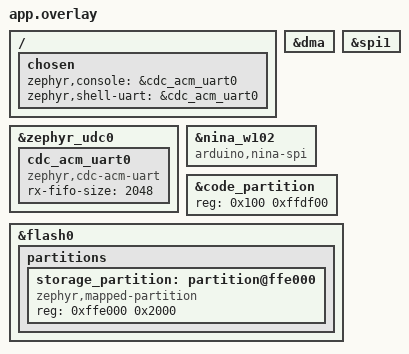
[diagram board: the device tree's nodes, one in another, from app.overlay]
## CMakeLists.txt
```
cmake_minimum_required(VERSION 3.28.0)
find_package(Zephyr REQUIRED HINTS $ENV{ZEPHYR_BASE})
project(usb_console)

target_sources(app PRIVATE src/main.c src/log_ram.c src/kv_store.c src/imu_cal.c src/imu_cal_codec.c src/wifi_profile.c
  src/time_sync.c src/time_offset.c
  src/imu_stream.c src/imu_raw_batch.c src/imu_raw_packet.c src/imu_raw_time.c
  src/imu_tick_clock.c src/imu_raw_queue.c src/imu_raw_mqtt.c src/imu_raw_status.c
  drivers/nina/nina_wifi.c drivers/nina/nina_net.c drivers/nina/nina_socket.c
  drivers/nina/nina_dns.c)
target_include_directories(app PRIVATE src drivers/lsm6dso)
# Keep Zephyr's Kconfig and devicetree bindings while using local driver copies.
function(use_local_driver_sources target pattern replacement_dir)
  get_target_property(sources ${target} SOURCES)
  set(updated_sources)
  set(replaced 0)
  foreach(source IN LISTS sources)
    if(source MATCHES "${pattern}")
      get_filename_component(filename "${source}" NAME)
      list(APPEND updated_sources "${CMAKE_CURRENT_SOURCE_DIR}/${replacement_dir}/${filename}")
      math(EXPR replaced "${replaced} + 1")
    else()
      list(APPEND updated_sources "${source}")
    endif()
  endforeach()
  if(replaced EQUAL 0)
    message(FATAL_ERROR "No sources replaced in ${target}; check the Zephyr version and configuration")
  endif()
  set_property(TARGET ${target} PROPERTY SOURCES "${updated_sources}")
endfunction()

use_local_driver_sources(drivers__i2c "(^|/)i2c_dw\\.c$" drivers/i2c_dw)
if(CONFIG_I2C_DW_RP2040_DMA)
  target_sources(drivers__i2c PRIVATE drivers/i2c_dw/i2c_dw_rp2040_commands.c)
endif()
target_include_directories(drivers__i2c PRIVATE "${ZEPHYR_BASE}/drivers/i2c")

use_local_driver_sources(drivers__sensor__st__lsm6dso "(^|/)lsm6dso(_shub|_trigger)?\\.c$" drivers/lsm6dso)
use_local_driver_sources(drivers__sensor "(^|/)sensor_shell\\.c$" drivers/sensor_shell)
target_include_directories(drivers__sensor PRIVATE ${ZEPHYR_BASE}/drivers/sensor)
target_sources(drivers__sensor__st__lsm6dso PRIVATE drivers/lsm6dso/lsm6dso_fifo.c)
target_sources(drivers__sensor__st__lsm6dso PRIVATE drivers/lsm6dso/lsm6dso_cal.c)
target_sources(drivers__sensor__st__lsm6dso PRIVATE drivers/lsm6dso/lsm6dso_fifo_hw.c)
target_sources(drivers__sensor__st__lsm6dso PRIVATE drivers/lsm6dso/lsm6dso_fifo_irq.c)
if(CONFIG_SENSOR_ASYNC_API)
  target_sources(drivers__sensor__st__lsm6dso PRIVATE
    drivers/lsm6dso/lsm6dso_fifo_decoder.c
    drivers/lsm6dso/lsm6dso_compat.c
    drivers/lsm6dso/lsm6dso_stream.c)
endif()
```

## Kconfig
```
mainmenu "USB console"
source "Kconfig.zephyr"

config I2C_DW_RP2040_DMA
	bool "RP2040 I2C0 DMA reads"
	depends on SOC_RP2040 && I2C_DW && DMA_RPI_PICO && SHELL && !SMP
	depends on !I2C_DW_LPSS_DMA

config WIFI_NINA_LOCAL
	bool "NINA SPI Wi-Fi offload"
	default y
	select NET_L2_WIFI_MGMT
	select WIFI_OFFLOAD
	select NET_SOCKETS
	select NET_SOCKETS_OFFLOAD

config NINA_SPI_FREQUENCY
	int "NINA SPI frequency in Hz"
	default 8000000
	range 1000000 10000000
	depends on WIFI_NINA_LOCAL

config NINA_TCP_MAX_IO
	int "Maximum bytes per NINA TCP send"
	default 3584
	range 1 3584
	depends on WIFI_NINA_LOCAL
	help
	  Bounds each TCP send to leave room for framing in the NINA SPI
	  command buffer. A RAW batch of up to 2448 bytes plus its MQTT
	  header is sent in one command with the default.

config NINA_SEND_RETRY_MS
	int "Delay before retrying a full NINA TCP send buffer"
	default 1
	range 1 1000
	depends on WIFI_NINA_LOCAL

config NINA_NTP_SERVER
	string "NTP server hostname or IPv4 address"
	default ""
	depends on WIFI_NINA_LOCAL
	help
	  Empty uses the default gateway, normally the PC that provides the
	  Wi-Fi network and runs an NTP server for the board.

config NINA_NTP_PORT
	int "NTP server UDP port"
	default 123
	range 1 65535
	depends on WIFI_NINA_LOCAL

config NINA_NTP_INTERVAL_MS
	int "Interval between NTP queries in milliseconds"
	default 2000
	range 250 3600000
	depends on WIFI_NINA_LOCAL
	help
	  Queries go to a server on the local network. Do not point short
	  intervals at public servers.

# Removed with the last cleanup step; lets a new image be written without
# pressing the BOOTSEL button while the cleanup is being verified.
config NINA_BENCHMARK_BOOTSEL
	bool "Enable BOOTSEL command"
	depends on SOC_RP2040 && SHELL
```

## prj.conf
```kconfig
CONFIG_SERIAL=y
CONFIG_CONSOLE=y
CONFIG_UART_CONSOLE=y
CONFIG_UART_LINE_CTRL=y
CONFIG_SHELL=y
# Keep Wi-Fi credentials out of shell command history.
CONFIG_SHELL_HISTORY=n
CONFIG_SHELL_BACKEND_SERIAL_RX_RING_BUFFER_SIZE=2048
CONFIG_SHELL_CMD_BUFF_SIZE=512
CONFIG_SHELL_STACK_SIZE=3072
CONFIG_MAIN_STACK_SIZE=2048
CONFIG_GPIO=y
CONFIG_GPIO_SHELL=y
CONFIG_I2C=y
CONFIG_SPI=y
CONFIG_I2C_SHELL=y
CONFIG_I2C_SHELL_BUFFER_SIZE=64
CONFIG_SENSOR=y
CONFIG_SENSOR_SHELL=y
CONFIG_SENSOR_SHELL_STREAM=y
CONFIG_SENSOR_SHELL_THREAD_STACK_SIZE=3072
CONFIG_STACK_SENTINEL=y
CONFIG_POLL=y
CONFIG_LSM6DSO=y
CONFIG_REBOOT=y
CONFIG_THREAD_ANALYZER=y
CONFIG_THREAD_ANALYZER_USE_PRINTK=y
CONFIG_LOG=y
CONFIG_LOG_OUTPUT=y
CONFIG_LOG_TIMESTAMP_64BIT=y
CONFIG_LOG_CMDS=y
CONFIG_LOG_RUNTIME_FILTERING=y
CONFIG_SHELL_LOG_BACKEND=n
CONFIG_LOG_BACKEND_UART=n

CONFIG_USB_DEVICE_STACK_NEXT=y
CONFIG_USBD_CDC_ACM_LOG_LEVEL_OFF=y
CONFIG_CDC_ACM_SERIAL_INITIALIZE_AT_BOOT=y
CONFIG_CDC_ACM_SERIAL_PID=0x0004
CONFIG_CDC_ACM_SERIAL_PRODUCT_STRING="Zephyr USB Console"

# Measure active time from CPU idle windows, including interrupts.
CONFIG_CPU_LOAD=y
CONFIG_CPU_LOAD_BACKEND_IDLE_HOOK=y

# Use DMA for eligible I2C0 reads.
CONFIG_DMA=y
CONFIG_I2C_DW_RP2040_DMA=y

# NINA Wi-Fi management and socket offload.
CONFIG_NETWORKING=y
CONFIG_WIFI=y
CONFIG_WIFI_CREDENTIALS=y
CONFIG_WIFI_CREDENTIALS_BACKEND_SETTINGS=y
CONFIG_WIFI_NINA_LOCAL=y
CONFIG_NET_IPV4=y
CONFIG_NET_TCP=y
CONFIG_SHELL_BACKEND_TELNET=y
CONFIG_ZVFS_POLL_MAX=16
CONFIG_NET_ZPERF=y
CONFIG_NET_ZPERF_IPERF3=y
CONFIG_NET_ZPERF_SERVER=y
CONFIG_NET_L2_WIFI_SHELL=y
CONFIG_NET_SHELL=y
CONFIG_MQTT_LIB=y
# Network event callbacks may print Wi-Fi results through the shell. Measured
# peak use is 924 bytes including a Wi-Fi scan.
CONFIG_NET_MGMT_EVENT_STACK_SIZE=2048
# Every socket is offloaded to the NINA, so Zephyr's own IP stack carries no
# traffic ("net conn" stays empty). Keep its packet buffers and connection
# tables at a minimum instead of the defaults sized for native networking.
CONFIG_NET_PKT_RX_COUNT=2
CONFIG_NET_PKT_TX_COUNT=2
CONFIG_NET_BUF_RX_COUNT=4
CONFIG_NET_BUF_TX_COUNT=4
CONFIG_NET_MAX_CONTEXTS=2
CONFIG_NET_MAX_CONN=2
# Zephyr derives the size of the file descriptor table from NET_MAX_CONTEXTS,
# which no longer reflects the sockets in use. Size it for the ten NINA
# sockets, stdin/stdout/stderr and the socket service's eventfd. With too few,
# accepting a Telnet client fails in a tight loop.
CONFIG_ZVFS_OPEN_MAX=16
CONFIG_WIFI_ESP_AT=n
# Temporary non-cryptographic random generator for network testing; no TLS.
CONFIG_TEST_RANDOM_GENERATOR=y
CONFIG_NET_IPV6=n

# Persist the most recently successful Wi-Fi connection.
CONFIG_FLASH=y
CONFIG_FLASH_MAP=y
CONFIG_NVS=y
CONFIG_SETTINGS=y
CONFIG_SETTINGS_NVS=y

# Identifies the board in automatically assigned IMU session IDs.
CONFIG_HWINFO=y
```

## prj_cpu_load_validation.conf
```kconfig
# Test-only synthetic thread and timer-ISR workload.
CONFIG_IMU_CPU_LOAD_VALIDATION=y
```

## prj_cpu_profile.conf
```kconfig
# Thread-only profiling; scheduler accounting includes interrupt time.
CONFIG_IMU_CPU_PROFILE=y
```

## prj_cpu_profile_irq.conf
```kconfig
# Optional IRQ sampling; can perturb high-rate I2C and cause FIFO overrun.
CONFIG_IMU_CPU_PROFILE=y
CONFIG_TRACING=y
CONFIG_TRACING_NONE=y
CONFIG_TRACING_ISR=y
CONFIG_IMU_CPU_PROFILE_IRQS=y
```

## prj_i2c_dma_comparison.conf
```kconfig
# Hardware validation commands for I2C DMA.
CONFIG_DMA=y
CONFIG_I2C_DW_RP2040_DMA=y
CONFIG_IMU_I2C_VALIDATION=y
CONFIG_IMU_CPU_LOAD_VALIDATION=y
CONFIG_I2C_SHELL_BUFFER_SIZE=64
```

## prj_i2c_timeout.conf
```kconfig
CONFIG_IMU_I2C_VALIDATION=y
CONFIG_I2C_TRANSFER_TIMEOUT_MS=2
```

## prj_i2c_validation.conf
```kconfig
CONFIG_IMU_I2C_VALIDATION=y
```

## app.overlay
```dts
/ {
	chosen {
		zephyr,console = &cdc_acm_uart0;
		zephyr,shell-uart = &cdc_acm_uart0;
	};
};

&zephyr_udc0 {
	cdc_acm_uart0: cdc_acm_uart0 {
		compatible = "zephyr,cdc-acm-uart";
		rx-fifo-size = <2048>;
	};
};

&dma {
	status = "okay";
};

&spi1 {
	status = "okay";
};

&nina_w102 {
	compatible = "arduino,nina-spi";
};

/* Reserve the last two erase sectors for settings; keep the image separate. */
&code_partition {
	reg = <0x100 0xffdf00>;
};

&flash0 {
	partitions {
		storage_partition: partition@ffe000 {
			compatible = "zephyr,mapped-partition";
			reg = <0xffe000 0x2000>;
		};
	};
};
```

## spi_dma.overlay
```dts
#include <zephyr/dt-bindings/dma/rpi-pico-dma-rp2040.h>

&spi1 {
	dmas = <&dma 0 RPI_PICO_DMA_SLOT_SPI1_TX 0>,
	       <&dma 1 RPI_PICO_DMA_SLOT_SPI1_RX 0>;
	dma-names = "tx", "rx";
};
```

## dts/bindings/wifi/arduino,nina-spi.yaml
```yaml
description: Arduino NINA WiFi firmware SPI interface
compatible: "arduino,nina-spi"
include: spi-device.yaml
properties:
  ready-gpios:
    type: phandle-array
    required: true
  reset-gpios:
    type: phandle-array
    required: true
  irq-gpios:
    type: phandle-array
    required: true
```

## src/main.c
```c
#include <zephyr/kernel.h>
#include <zephyr/debug/thread_analyzer.h>
#include <zephyr/logging/log.h>
#include <zephyr/shell/shell.h>
#include "wifi_profile.h"
#include "../drivers/nina/nina_proto.h"
#include "time_sync.h"
#include "imu_cal.h"
#include "kv_store.h"

LOG_MODULE_REGISTER(usb_console, LOG_LEVEL_INF);

static int cmd_nina_version(const struct shell *sh, size_t argc, char **argv)
{
	uint8_t version[16];
	size_t len;
	int ret;

	ARG_UNUSED(argc);
	ARG_UNUSED(argv);
	ret = nina_request(0x37, NULL, 0, false, false, version, sizeof(version) - 1, &len);
	if (ret) {
		shell_error(sh, "NINA version request failed: %d", ret);
		return ret;
	}
	version[len] = '\0';
	shell_print(sh, "NINA firmware: %s", version);
	return 0;
}

SHELL_STATIC_SUBCMD_SET_CREATE(nina_commands,
	SHELL_CMD(version, NULL, "Show NINA firmware version", cmd_nina_version),
	SHELL_SUBCMD_SET_END);
SHELL_CMD_REGISTER(nina, &nina_commands, "NINA Wi-Fi module", NULL);

/* Thread Analyzer's callback has no user context, so serialize access to it. */
K_MUTEX_DEFINE(ps_lock);
static const struct shell *ps_shell;

static void ps_print_thread(struct thread_analyzer_info *info)
{
	shell_print(ps_shell, "%-20s CPU: %3u%%  STACK: %zu / %zu bytes",
		    info->name, info->utilization, info->stack_used,
		    info->stack_size);
}

static int cmd_ps(const struct shell *sh, size_t argc, char **argv)
{
	ARG_UNUSED(argc);
	ARG_UNUSED(argv);
	k_mutex_lock(&ps_lock, K_FOREVER);
	ps_shell = sh;
	thread_analyzer_run(ps_print_thread, 0);
	ps_shell = NULL;
	k_mutex_unlock(&ps_lock);
	return 0;
}

SHELL_SUBCMD_ADD((kernel), ps, NULL, "Show thread CPU and stack usage", cmd_ps,
		 1, 0);

int main(void)
{
	int ret;

	LOG_INF("USB console started");
	ret = kv_store_init();
	if (ret) {
		LOG_ERR("Could not initialize settings: %d", ret);
	}
	ret = imu_cal_init();
	if (ret) {
		LOG_ERR("Could not set up the IMU calibration: %d", ret);
	}
	time_sync_init();
	(void)wifi_profile_init();
	return 0;
}
```

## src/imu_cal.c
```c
/* SPDX-License-Identifier: Apache-2.0 */

#include <errno.h>
#include <stdlib.h>
#include <string.h>
#include <zephyr/device.h>
#include <zephyr/devicetree.h>
#include <zephyr/shell/shell.h>
#include <zephyr/sys/printk.h>
#include "imu_cal.h"
#include "kv_store.h"

static const struct device *const imu = DEVICE_DT_GET(DT_NODELABEL(lsm6dsox));

static bool lookup(enum lsm6dso_cal_kind kind, uint32_t gain, struct lsm6dso_cal *cal)
{
	char key[IMU_CAL_KEY_MAX];
	uint8_t blob[IMU_CAL_BLOB_SIZE];
	ssize_t len;

	if (imu_cal_key(kind, gain, key, sizeof(key)) < 0) {
		return false;
	}
	len = kv_store_get(key, blob, sizeof(blob));
	return len > 0 && imu_cal_decode(blob, len, kind, gain, cal) == 0;
}

int imu_cal_init(void)
{
	if (!device_is_ready(imu)) {
		return -ENODEV;
	}
	lsm6dso_cal_set_lookup(imu, lookup);
	return 0;
}

static void print_one(const struct shell *sh, const char *name, const char *unit,
		      enum lsm6dso_cal_kind kind, uint32_t gain, bool calibrated)
{
	char key[IMU_CAL_KEY_MAX];

	(void)imu_cal_key(kind, gain, key, sizeof(key));
	shell_print(sh, "  %-6s %s (%u %s/LSB, key %s)", name,
		    calibrated ? "calibrated" : "nominal", (unsigned int)gain, unit, key);
}

/* Prints one bias value, kept as LSB << 8, with two decimals. */
static void format_bias(char *text, size_t size, int32_t value)
{
	int32_t hundredths = (int32_t)(((int64_t)value * 100 +
					(value >= 0 ? 128 : -128)) / 256);

	snprintk(text, size, "%s%d.%02d", hundredths < 0 ? "-" : "",
		 (int)(abs(hundredths) / 100), (int)(abs(hundredths) % 100));
}

static void print_bias(const struct shell *sh, const struct lsm6dso_cal_status *status)
{
	char x[12], y[12], z[12];

	format_bias(x, sizeof(x), status->gyro_bias[0]);
	format_bias(y, sizeof(y), status->gyro_bias[1]);
	format_bias(z, sizeof(z), status->gyro_bias[2]);
	if (status->gyro_bias_updates > 0) {
		shell_print(sh, "  gyro bias: %s %s %s LSB (tracked at rest, %u updates, %u rejected)",
			    x, y, z, (unsigned int)status->gyro_bias_updates,
			    (unsigned int)status->gyro_bias_rejected);
	} else {
		shell_print(sh, "  gyro bias: %s %s %s LSB (%s, %u rejected)", x, y, z,
			    status->gyro_calibrated ? "stored" : "none",
			    (unsigned int)status->gyro_bias_rejected);
	}
}

int imu_cal_shell(const struct shell *sh, size_t argc, char **argv)
{
	struct lsm6dso_cal_status status;

	if (!device_is_ready(imu)) {
		shell_error(sh, "IMU not ready");
		return -ENODEV;
	}
	if (argc > 1 && strcmp(argv[1], "reload") == 0) {
		lsm6dso_cal_reload(imu);
	} else if (argc > 1 && strcmp(argv[1], "zero") == 0) {
		int ret = lsm6dso_cal_zero(imu);

		if (ret == -EBUSY) {
			shell_error(sh, "The sensor is streaming; the bias is tracked from the stream");
		} else if (ret == -EAGAIN) {
			shell_error(sh, "The sensor did not stay at rest");
		} else if (ret == -ERANGE) {
			shell_error(sh, "The reading is too far from the stored bias");
		} else if (ret) {
			shell_error(sh, "Could not read the sensor: %d", ret);
		}
		if (ret) {
			return ret;
		}
	} else if (argc > 1) {
		shell_error(sh, "usage: imu cal [reload|zero]");
		return -EINVAL;
	}
	lsm6dso_cal_status(imu, &status);
	shell_print(sh, "conversion:");
	print_one(sh, "accel:", "ug", LSM6DSO_CAL_ACCEL, status.accel_gain, status.accel_calibrated);
	print_one(sh, "gyro:", "udps", LSM6DSO_CAL_GYRO, status.gyro_gain, status.gyro_calibrated);
	print_bias(sh, &status);
	return 0;
}
```

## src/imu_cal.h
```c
/* SPDX-License-Identifier: Apache-2.0 */
#ifndef APP_IMU_CAL_H_
#define APP_IMU_CAL_H_

#include <stddef.h>
#include <stdint.h>
#include "lsm6dso_cal.h"

/* Calibration values are kept in the KV store, one entry per sensor and
 * sensitivity:
 *
 *   imu.cal.accel.<ug per LSB>     imu.cal.gyro.<udps per LSB>
 *
 * An entry applies only while the sensor runs at that sensitivity, so a range
 * that was never calibrated falls back to the nominal conversion.  The value
 * is 56 bytes, little-endian:
 *
 *   u8  version (1)
 *   u8  kind (0 accel, 1 gyro)
 *   u16 reserved (0)
 *   u32 sensitivity, as in the key
 *   i32 m[3][3]   row-major, see struct lsm6dso_cal
 *   i32 bias[3]
 */
#define IMU_CAL_VERSION   1
#define IMU_CAL_BLOB_SIZE 56
#define IMU_CAL_KEY_MAX   32

/* Writes the KV key for a sensor and sensitivity. Returns the length, or a
 * negative errno if it does not fit.
 */
int imu_cal_key(enum lsm6dso_cal_kind kind, uint32_t gain, char *key, size_t capacity);
/* Decodes a stored value. Returns 0, or a negative errno if the value is not a
 * calibration for this sensor and sensitivity.
 */
int imu_cal_decode(const uint8_t *blob, size_t len, enum lsm6dso_cal_kind kind, uint32_t gain,
		   struct lsm6dso_cal *cal);

/* Makes the IMU driver use the stored calibration. Call after kv_store_init(). */
int imu_cal_init(void);

struct shell;
/* "imu cal [reload|zero]": shows the conversion in use, after reading the KV store
 * again or taking the gyro bias from the sensor at rest when asked.
 */
int imu_cal_shell(const struct shell *sh, size_t argc, char **argv);

#endif
```

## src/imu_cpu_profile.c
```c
/* SPDX-License-Identifier: Apache-2.0 */
#include "imu_cpu_profile.h"
#ifdef CONFIG_IMU_CPU_PROFILE_IRQS
#include <cmsis_core.h>
#include <hardware/platform_defs.h>
#include <hardware/regs/i2c.h>
#include <zephyr/sys/sys_io.h>
#endif
#include <inttypes.h>
#include <string.h>
#include <zephyr/irq.h>
#include <zephyr/kernel.h>

#define PROFILE_THREADS       32
#define PROFILE_EXCEPTIONS    48
#define PROFILE_SAMPLE_PERIOD 61U

struct thread_entry {
	k_tid_t id;
	char name[24];
	uint64_t cycles;
};
#ifdef CONFIG_IMU_CPU_PROFILE_IRQS
struct irq_entry {
	uint64_t cycles;
	uint64_t idle_cycles;
	uint32_t count;
	uint32_t samples;
	uint32_t started;
	bool sampling;
	bool interrupted_idle;
};
static struct irq_entry irq_data[PROFILE_EXCEPTIONS];
/* Sampled masked I2C interrupt conditions: neither, TX only, RX only, both. */
static uint32_t i2c_status_samples[4];
static uint32_t i2c_tx_only_rx_empty;
static uint32_t irq_overflow;
static volatile bool active;
static k_tid_t idle_thread;

/* Each vector samples one in 61 invocations. The same exception cannot
 * preempt itself on Cortex-M. Sampled times include any nested exceptions.
 */
void sys_trace_isr_enter(void)
{
	uint32_t vector;
	struct irq_entry *entry;

	if (!active) {
		return;
	}
	vector = __get_IPSR();
	if (vector >= PROFILE_EXCEPTIONS) {
		irq_overflow++;
		return;
	}
	entry = &irq_data[vector];
	entry->count++;
	entry->sampling = (entry->count % PROFILE_SAMPLE_PERIOD) == 1;
	if (entry->sampling) {
		if (vector == DT_IRQN(DT_NODELABEL(i2c0)) + 16) {
			uint32_t status = sys_read32(DT_REG_ADDR(DT_NODELABEL(i2c0)) +
						     I2C_IC_INTR_STAT_OFFSET);
			unsigned int category =
				(status & I2C_IC_INTR_STAT_R_TX_EMPTY_BITS ? 1U : 0U) |
				(status & I2C_IC_INTR_STAT_R_RX_FULL_BITS ? 2U : 0U);
			i2c_status_samples[category]++;
			if (category == 1 && sys_read32(DT_REG_ADDR(DT_NODELABEL(i2c0)) +
							I2C_IC_RXFLR_OFFSET) == 0) {
				i2c_tx_only_rx_empty++;
			}
		}
		entry->interrupted_idle = k_current_get() == idle_thread;
		entry->started = k_cycle_get_32();
	}
}

void sys_trace_isr_exit(void)
{
	uint32_t vector;
	struct irq_entry *entry;
	uint32_t elapsed;

	if (!active) {
		return;
	}
	vector = __get_IPSR();
	if (vector >= PROFILE_EXCEPTIONS) {
		return;
	}
	entry = &irq_data[vector];
	if (entry->sampling) {
		elapsed = k_cycle_get_32() - entry->started;
		entry->cycles += elapsed;
		entry->samples++;
		if (entry->interrupted_idle) {
			entry->idle_cycles += elapsed;
		}
		entry->sampling = false;
	}
}

#endif /* CONFIG_IMU_CPU_PROFILE_IRQS */

static struct thread_entry before[PROFILE_THREADS], after[PROFILE_THREADS];
static unsigned int before_count, after_count, thread_overflow;

struct thread_capture {
	struct thread_entry *entries;
	unsigned int count;
};
static void capture_thread(const struct k_thread *thread, void *arg)
{
	struct thread_capture *capture = arg;
	k_thread_runtime_stats_t stats;
	const char *name;
	struct thread_entry *entry;

	if (capture->count >= PROFILE_THREADS) {
		thread_overflow++;
		return;
	}
	if (k_thread_runtime_stats_get((k_tid_t)thread, &stats) != 0) {
		thread_overflow++;
		return;
	}
	entry = &capture->entries[capture->count++];
	entry->id = (k_tid_t)thread;
	entry->cycles = stats.execution_cycles;
	name = k_thread_name_get((k_tid_t)thread);
	if (name) {
		strncpy(entry->name, name, sizeof(entry->name) - 1);
		entry->name[sizeof(entry->name) - 1] = '\0';
	} else {
		entry->name[0] = '\0';
	}
}
static unsigned int capture_threads(struct thread_entry *entries)
{
	struct thread_capture capture = {.entries = entries};
	k_thread_foreach(capture_thread, &capture);
	return capture.count;
}
void imu_cpu_profile_start(void)
{
#ifdef CONFIG_IMU_CPU_PROFILE_IRQS
	unsigned int key;
#endif
	thread_overflow = 0;
	before_count = capture_threads(before);
#ifdef CONFIG_IMU_CPU_PROFILE_IRQS
	idle_thread = NULL;
	for (unsigned int i = 0; i < before_count; i++) {
		if (!strcmp(before[i].name, "idle")) {
			idle_thread = before[i].id;
			break;
		}
	}
	key = irq_lock();
	memset(irq_data, 0, sizeof(irq_data));
	memset(i2c_status_samples, 0, sizeof(i2c_status_samples));
	i2c_tx_only_rx_empty = 0;
	irq_overflow = 0;
	active = true;
	irq_unlock(key);
#endif
}
void imu_cpu_profile_stop(void)
{
#ifdef CONFIG_IMU_CPU_PROFILE_IRQS
	unsigned int key = irq_lock();
	active = false;
	irq_unlock(key);
#endif
	after_count = capture_threads(after);
}
#ifdef CONFIG_IMU_CPU_PROFILE_IRQS
static const char *irq_label(unsigned int irq)
{
	if (irq == 15) {
		return "systick";
	}
	if (irq < 16) {
		return "exception";
	}
	irq -= 16;
	if (irq == DT_IRQN(DT_NODELABEL(i2c0))) {
		return "i2c0";
	}
	if (irq == DT_IRQN(DT_NODELABEL(gpio0_map))) {
		return "gpio0";
	}
	return "other";
}
#endif
void imu_cpu_profile_print(const struct shell *shell, uint64_t total_cycles, uint64_t busy_cycles)
{
	if (!total_cycles) {
		shell_print(shell, "CPU profile unavailable");
		return;
	}
#ifdef CONFIG_IMU_CPU_PROFILE_IRQS
	if (idle_thread) {
		uint64_t idle_irq_cycles = 0;
		for (unsigned int i = 0; i < PROFILE_EXCEPTIONS; i++) {
			if (irq_data[i].samples) {
				idle_irq_cycles += irq_data[i].idle_cycles * irq_data[i].count /
						   irq_data[i].samples;
			}
		}
		uint64_t pct = (busy_cycles + idle_irq_cycles) * 10000ULL / total_cycles;
		shell_print(shell,
			    "busy_with_sampled_idle_irq=%" PRIu64 ".%02" PRIu64
			    "%% (estimate; nested IRQ may overlap)",
			    pct / 100, pct % 100);
	} else {
		shell_print(shell, "idle thread not identified; corrected busy unavailable");
	}
#else
	ARG_UNUSED(busy_cycles);
#endif
	shell_print(shell, "CPU profile: scheduler thread time (includes interrupts)");
	for (unsigned int i = 0; i < after_count; i++) {
		for (unsigned int j = 0; j < before_count; j++) {
			if (after[i].id == before[j].id && after[i].cycles >= before[j].cycles) {
				uint64_t cycles = after[i].cycles - before[j].cycles;
				uint64_t pct = cycles * 10000ULL / total_cycles;
				if (pct) {
					shell_print(shell,
						    "thread %s (%p): %" PRIu64 ".%02" PRIu64 "%%",
						    after[i].name[0] ? after[i].name : "unnamed",
						    (void *)after[i].id, pct / 100, pct % 100);
				}
				break;
			}
		}
	}
#ifdef CONFIG_IMU_CPU_PROFILE_IRQS
	shell_print(shell, "Sampled interrupts: 1/61, estimated inclusive time; overlaps threads");
	for (unsigned int i = 0; i < PROFILE_EXCEPTIONS; i++) {
		if (irq_data[i].count) {
			uint64_t cycles = irq_data[i].samples
						  ? irq_data[i].cycles * irq_data[i].count /
							    irq_data[i].samples
						  : 0;
			uint64_t pct = cycles * 10000ULL / total_cycles;
			shell_print(shell,
				    "vector %u (%s): ~%" PRIu64 ".%02" PRIu64
				    "%% count=%u samples=%u",
				    i, irq_label(i), pct / 100, pct % 100, irq_data[i].count,
				    irq_data[i].samples);
		}
	}
	shell_print(shell, "i2c_status_samples tx_only=%u rx_only=%u both=%u neither=%u",
		    i2c_status_samples[1], i2c_status_samples[2], i2c_status_samples[3],
		    i2c_status_samples[0]);
	shell_print(shell, "i2c_tx_only_samples_rx_fifo_empty=%u", i2c_tx_only_rx_empty);
	shell_print(shell, "profile_overflow threads=%u irq=%u", thread_overflow, irq_overflow);
#else
	shell_print(shell, "profile_overflow threads=%u; interrupts not measured", thread_overflow);
#endif
}
```

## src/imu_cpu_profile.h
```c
/* SPDX-License-Identifier: Apache-2.0 */
#ifndef IMU_CPU_PROFILE_H_
#define IMU_CPU_PROFILE_H_
#include <stdint.h>
#include <zephyr/shell/shell.h>
#ifdef CONFIG_IMU_CPU_PROFILE
void imu_cpu_profile_start(void);
void imu_cpu_profile_stop(void);
void imu_cpu_profile_print(const struct shell *shell, uint64_t total_cycles, uint64_t busy_cycles);
#else
static inline void imu_cpu_profile_start(void)
{
}
static inline void imu_cpu_profile_stop(void)
{
}
static inline void imu_cpu_profile_print(const struct shell *shell, uint64_t total_cycles,
					 uint64_t busy_cycles)
{
	(void)shell;
	(void)total_cycles;
	(void)busy_cycles;
}
#endif
#endif
```

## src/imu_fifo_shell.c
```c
/* SPDX-License-Identifier: Apache-2.0 */
#include <inttypes.h>
#include <zephyr/device.h>
#include <zephyr/devicetree.h>
#include <zephyr/shell/shell.h>
#include "../drivers/lsm6dso/lsm6dso_fifo_stats.h"

static int cmd_imu_fifo_stats(const struct shell *shell, size_t argc, char **argv)
{
	const struct device *dev = DEVICE_DT_GET(DT_NODELABEL(lsm6dsox));
	struct lsm6dso_fifo_stats stats;

	ARG_UNUSED(argc);
	ARG_UNUSED(argv);
	if (!device_is_ready(dev)) {
		return -ENODEV;
	}
	lsm6dso_fifo_get_stats(dev, &stats);
	shell_print(shell, "words=%" PRIu64 " transfers=%" PRIu32,
		    stats.words_read, stats.transfers);
	shell_print(shell, "transfer_ns=%" PRIu64 " max_transfer_ns=%" PRIu64,
		    stats.transfer_time_ns, stats.max_transfer_time_ns);
	shell_print(shell, "i2c_errors=%" PRIu32 " buffer_too_small=%" PRIu32
		    " overrun_observations=%" PRIu32,
		    stats.i2c_errors, stats.buffer_too_small, stats.overrun_observations);
	return 0;
}

SHELL_CMD_REGISTER(imu_fifo_stats, NULL, "Show IMU FIFO counters", cmd_imu_fifo_stats);
```

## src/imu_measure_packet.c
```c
/* SPDX-License-Identifier: Apache-2.0 */
#include <errno.h>
#include <stdbool.h>
#include <stddef.h>
#include <string.h>
#include "imu_measure_packet.h"
#include "../drivers/lsm6dso/lsm6dso_fifo.h"
#include "../drivers/lsm6dso/lsm6dso_fifo_decoder.h"

int imu_measure_count_packet(const uint8_t *buffer, size_t length,
			     struct imu_measure_counts *counts)
{
	const struct lsm6dso_fifo_packet *packet = (const void *)buffer;
	struct lsm6dso_fifo_sample sample;
	size_t cursor = 0;
	uint64_t accel = 0, gyro = 0, other = 0;
#if defined(CONFIG_NINA_SEND_PROFILE)
	bool valid_after_other = false;
#endif
	int ret;

	if (!buffer || !counts || length < offsetof(struct lsm6dso_fifo_packet, data) ||
	    packet->marker != LSM6DSO_FIFO_PACKET_MARKER ||
	    packet->words > LSM6DSO_FIFO_MAX_WORDS ||
	    length - offsetof(struct lsm6dso_fifo_packet, data) <
		(size_t)packet->words * LSM6DSO_FIFO_WORD_SIZE) {
		return -EINVAL;
	}
	/* Count unknown tags too; silently discarding them could hide a format
	 * mismatch or a sensor configuration change during a measurement.
	 */
	for (size_t i = 0; i < packet->words; i++) {
		ret = lsm6dso_fifo_decode_word(packet->data + cursor, &sample);
		if (ret == 0) {
#if defined(CONFIG_NINA_SEND_PROFILE)
			valid_after_other |= other != 0;
#endif
			accel += sample.kind == LSM6DSO_FIFO_ACCEL;
			gyro += sample.kind == LSM6DSO_FIFO_GYRO;
		} else if (ret == -ENOTSUP) {
			other++;
#if defined(CONFIG_NINA_SEND_PROFILE)
			if (!counts->other_words && other == 1) {
				memcpy(counts->first_other, packet->data + cursor,
				       sizeof(counts->first_other));
				counts->first_other_index = i;
				counts->first_other_packet_words = packet->words;
			}
			counts->other_tags[packet->data[cursor] >> 3]++;
#endif
		} else {
			return ret;
		}
		cursor += LSM6DSO_FIFO_WORD_SIZE;
	}
	counts->batches++;
	counts->accel_samples += accel;
	counts->gyro_samples += gyro;
	counts->other_words += other;
#if defined(CONFIG_NINA_SEND_PROFILE)
	counts->batches_with_other += other != 0;
	counts->batches_valid_after_other += valid_after_other;
#endif
	return 0;
}

enum imu_measure_accounting imu_measure_check_accounting(const struct imu_measure_counts *counts,
							 uint64_t fifo_words, uint64_t fifo_transfers,
							 int complete)
{
	uint64_t words;

	if (!counts || !complete) {
		return IMU_MEASURE_ACCOUNTING_INCOMPLETE;
	}
	if (counts->accel_samples > UINT64_MAX - counts->gyro_samples) {
		return IMU_MEASURE_ACCOUNTING_MISMATCH;
	}
	words = counts->accel_samples + counts->gyro_samples;
	if (words > UINT64_MAX - counts->other_words) {
		return IMU_MEASURE_ACCOUNTING_MISMATCH;
	}
	words += counts->other_words;
	return words == fifo_words && counts->batches == fifo_transfers ?
		IMU_MEASURE_ACCOUNTING_MATCH : IMU_MEASURE_ACCOUNTING_MISMATCH;
}
```

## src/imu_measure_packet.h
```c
/* SPDX-License-Identifier: Apache-2.0 */
#ifndef IMU_MEASURE_PACKET_H_
#define IMU_MEASURE_PACKET_H_

#include <stddef.h>
#include <stdint.h>

struct imu_measure_counts {
	uint64_t batches;
	uint64_t accel_samples;
	uint64_t gyro_samples;
	uint64_t other_words;
#if defined(CONFIG_NINA_SEND_PROFILE)
	uint32_t other_tags[32];
	uint8_t first_other[7];
	uint32_t first_other_index, first_other_packet_words;
	uint32_t batches_with_other, batches_valid_after_other;
#endif
};

enum imu_measure_accounting {
	IMU_MEASURE_ACCOUNTING_INCOMPLETE,
	IMU_MEASURE_ACCOUNTING_MATCH,
	IMU_MEASURE_ACCOUNTING_MISMATCH,
};

int imu_measure_count_packet(const uint8_t *buffer, size_t length,
			     struct imu_measure_counts *counts);
enum imu_measure_accounting imu_measure_check_accounting(const struct imu_measure_counts *counts,
							 uint64_t fifo_words, uint64_t fifo_transfers,
							 int complete);
#endif
```

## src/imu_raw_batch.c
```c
/* SPDX-License-Identifier: Apache-2.0 */
#include "imu_raw_batch.h"

#include <errno.h>
#include <stdbool.h>
#include <string.h>

int imu_raw_batch_init(struct imu_raw_batch *batch, const uint8_t session_id[16],
		       uint32_t epoch_id, imu_raw_batch_sink sink, void *context)
{
	if (!batch || !session_id || !sink) {
		return -EINVAL;
	}
	memset(batch, 0, sizeof(*batch));
	memcpy(batch->meta.session_id, session_id, sizeof(batch->meta.session_id));
	batch->meta.epoch_id = epoch_id;
	batch->meta.accel_first_index = UINT64_MAX;
	batch->meta.gyro_first_index = UINT64_MAX;
	batch->sink = sink;
	batch->sink_context = context;
	imu_raw_time_init(&batch->time);
	imu_raw_stage_reset(batch->payload);
	return 0;
}

/* Keeps a noted tick only if its timestamp has been confirmed since and
 * nothing invalidated it, then asks the clock for server time. Run once per
 * flush attempt; a batch kept after a sink error is settled again. */
static void settle_one(struct imu_raw_batch *batch, bool noted, uint32_t generation,
		       uint64_t *tick, uint64_t *unix_us, uint8_t tick_flag, uint8_t unix_flag)
{
	batch->meta.flags &= (uint8_t)~(tick_flag | unix_flag);
	*unix_us = 0;
	if (!noted || generation != batch->time.generation ||
	    !imu_raw_time_confirmed(&batch->time)) {
		return;
	}
	batch->meta.flags |= tick_flag;
	if (batch->clock && batch->clock(batch->clock_context, *tick, unix_us)) {
		batch->meta.flags |= unix_flag;
	} else {
		*unix_us = 0;
	}
}

static void settle_times(struct imu_raw_batch *batch)
{
	struct imu_raw_metadata *m = &batch->meta;
	/* The clock wants ticks in non-decreasing order. */
	bool accel_first = !batch->gyro_tick_noted ||
			   (batch->accel_tick_noted &&
			    batch->accel_noted_tick <= batch->gyro_noted_tick);

	for (int pass = 0; pass < 2; pass++) {
		if ((pass == 0) == accel_first) {
			settle_one(batch, batch->accel_tick_noted, batch->accel_tick_generation,
				   &batch->accel_noted_tick, &m->accel_first_unix_us,
				   IMU_RAW_ACCEL_TIME_VALID,
				   IMU_RAW_ACCEL_UNIX_VALID);
		} else {
			settle_one(batch, batch->gyro_tick_noted, batch->gyro_tick_generation,
				   &batch->gyro_noted_tick, &m->gyro_first_unix_us,
				   IMU_RAW_GYRO_TIME_VALID,
				   IMU_RAW_GYRO_UNIX_VALID);
		}
	}
	/* The encoder requires a tick of zero unless it is marked valid. */
	m->accel_first_tick = (m->flags & IMU_RAW_ACCEL_TIME_VALID) ? batch->accel_noted_tick : 0;
	m->gyro_first_tick = (m->flags & IMU_RAW_GYRO_TIME_VALID) ? batch->gyro_noted_tick : 0;
}

int imu_raw_batch_flush(struct imu_raw_batch *batch)
{
	size_t written;
	int rc;

	if (!batch || !batch->sink) {
		return -EINVAL;
	}
	if (!batch->count) {
		return 0;
	}
	if (batch->next_batch == UINT64_MAX) {
		return -EOVERFLOW;
	}
	batch->meta.batch_seq = batch->next_batch;
	settle_times(batch);
	rc = imu_raw_stage_finish(batch->payload, &written, &batch->meta, batch->count,
				  batch->accel_count);
	if (rc) {
		return rc;
	}
	rc = batch->sink(batch->sink_context, batch->payload, written);
	if (rc && rc != -EAGAIN) {
		/* Keep the batch so that a later flush can deliver it. */
		imu_raw_stage_reopen(batch->payload, batch->count);
		return rc;
	}
	if (rc == -EAGAIN) {
		batch->dropped_batches++;
		batch->dropped_accel += batch->accel_count;
		batch->dropped_gyro += batch->count - batch->accel_count;
	} else {
		batch->delivered_batches++;
	}
	batch->next_batch++;
	batch->count = 0;
	batch->accel_count = 0;
	imu_raw_stage_reset(batch->payload);
	batch->meta.accel_first_index = UINT64_MAX;
	batch->meta.gyro_first_index = UINT64_MAX;
	batch->meta.accel_first_tick = 0;
	batch->meta.gyro_first_tick = 0;
	batch->meta.accel_first_unix_us = 0;
	batch->meta.gyro_first_unix_us = 0;
	batch->meta.flags = 0;
	batch->accel_tick_noted = false;
	batch->gyro_tick_noted = false;
	return 0;
}

int imu_raw_batch_new_epoch(struct imu_raw_batch *batch)
{
	int rc;

	if (!batch || !batch->sink) {
		return -EINVAL;
	}
	if (batch->meta.epoch_id == UINT32_MAX) {
		return -EOVERFLOW;
	}
	rc = imu_raw_batch_flush(batch);
	if (rc) {
		return rc;
	}
	batch->meta.epoch_id++;
	imu_raw_time_new_epoch(&batch->time);
	return 0;
}

int imu_raw_batch_consume(struct imu_raw_batch *batch, const uint8_t *words,
			  size_t length, size_t *cursor)
{
	struct lsm6dso_fifo_entry entry;
	size_t next;
	int rc;

	if (!batch || !batch->sink || !cursor) {
		return -EINVAL;
	}
	for (;;) {
		next = *cursor;
		rc = lsm6dso_fifo_next_entry(words, length, &next, &entry);
		if (rc <= 0) {
			return rc;
		}
		if (entry.type == LSM6DSO_FIFO_ENTRY_OTHER) {
			return -EPROTO;
		}
		if (entry.type == LSM6DSO_FIFO_ENTRY_TIMESTAMP) {
			if (batch->timestamp_words == UINT64_MAX) {
				return -EOVERFLOW;
			}
			batch->timestamp_words++;
			imu_raw_time_timestamp(&batch->time, entry.timestamp, entry.counter);
			*cursor = next;
			continue;
		}
		if (batch->count == IMU_RAW_MAX_WORDS) {
			rc = imu_raw_batch_flush(batch);
			if (rc) {
				return rc;
			}
		}
		if ((entry.sample.kind == LSM6DSO_FIFO_ACCEL ? batch->next_accel :
		     batch->next_gyro) == UINT64_MAX) {
			return -EOVERFLOW;
		}
		/* Every sample advances the slot tracking, not only the first. */
		imu_raw_time_advance(&batch->time, entry.counter);
		if (entry.sample.kind == LSM6DSO_FIFO_ACCEL) {
			if (batch->meta.accel_first_index == UINT64_MAX) {
				batch->meta.accel_first_index = batch->next_accel;
				batch->accel_tick_noted =
					imu_raw_time_get(&batch->time, &batch->accel_noted_tick);
				batch->accel_tick_generation = batch->time.generation;
			}
			batch->next_accel++;
		} else {
			if (batch->meta.gyro_first_index == UINT64_MAX) {
				batch->meta.gyro_first_index = batch->next_gyro;
				batch->gyro_tick_noted =
					imu_raw_time_get(&batch->time, &batch->gyro_noted_tick);
				batch->gyro_tick_generation = batch->time.generation;
			}
			batch->next_gyro++;
		}
		imu_raw_stage_put(batch->payload, batch->count++, &entry.sample);
		batch->accel_count += entry.sample.kind == LSM6DSO_FIFO_ACCEL;
		*cursor = next;
		if (batch->count == IMU_RAW_MAX_WORDS) {
			rc = imu_raw_batch_flush(batch);
			if (rc) {
				return rc;
			}
		}
	}
}
```

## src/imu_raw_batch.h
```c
/* SPDX-License-Identifier: Apache-2.0 */
#ifndef IMU_RAW_BATCH_H_
#define IMU_RAW_BATCH_H_

#include "imu_raw_packet.h"
#include "imu_raw_time.h"

/* Runs in the FIFO consumer. The sink must not wait or retain payload; it
 * returns 0 after copying or -EAGAIN if it cannot accept the batch. */
typedef int (*imu_raw_batch_sink)(void *context, const uint8_t *payload, size_t length);
/* Optional: server (Unix) time in microseconds for a sensor tick. Called at
 * most twice per batch with ticks that never decrease. Must not wait long. */
typedef bool (*imu_raw_batch_clock)(void *context, uint64_t tick, uint64_t *unix_us);

struct imu_raw_batch {
	struct imu_raw_metadata meta;
	uint8_t payload[IMU_RAW_MAX_SIZE]; /* built in place, see imu_raw_stage_put() */
	uint64_t next_accel, next_gyro, next_batch;
	uint64_t delivered_batches, dropped_batches, dropped_accel, dropped_gyro;
	uint64_t timestamp_words;
	struct imu_raw_time time;
	size_t count, accel_count; /* words in the batch being built */
	imu_raw_batch_sink sink;
	void *sink_context;
	imu_raw_batch_clock clock; /* set after init; NULL leaves Unix time invalid */
	void *clock_context;
};

/* The caller supplies a unique session ID; no random ID is generated here. */
int imu_raw_batch_init(struct imu_raw_batch *batch, const uint8_t session_id[16],
		       uint32_t epoch_id, imu_raw_batch_sink sink, void *context);
/* cursor is a byte offset into a FIFO word array. Each valid sample is
 * numbered before the sink is called. The first accelerometer and gyroscope
 * sample of a batch carry their sensor tick when imu_raw_time can assign one;
 * otherwise the time-valid flag stays clear.
 * Unsupported tags return -EPROTO without consuming the offending word.
 */
int imu_raw_batch_consume(struct imu_raw_batch *batch, const uint8_t *words,
			  size_t length, size_t *cursor);
/* Flush the incomplete batch at a deadline, stop, or before an epoch change. */
int imu_raw_batch_flush(struct imu_raw_batch *batch);
/* Call after an unknown number of samples was lost (FIFO overrun, restart,
 * unparsable word). Flushes what was collected and starts the next epoch.
 * Batch and sample numbers keep counting so they stay unique in the session;
 * consecutive numbers on both sides of an epoch change do not mean that the
 * samples are contiguous. On a flush error the epoch is left unchanged.
 */
int imu_raw_batch_new_epoch(struct imu_raw_batch *batch);
#endif
```

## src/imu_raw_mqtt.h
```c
/* SPDX-License-Identifier: Apache-2.0 */
#ifndef IMU_RAW_MQTT_H_
#define IMU_RAW_MQTT_H_
#include <stdbool.h>
#include <stddef.h>
#include <stdint.h>
#include <zephyr/net/net_ip.h>
#include "imu_raw_status.h"

/* MQTT transport for RAW batches (QoS 0), info and status. It owns a bounded
 * queue: batches are dropped and counted while disconnected or when the
 * queue is full, never retried. Thread context only. */
#define IMU_RAW_MQTT_DEVICE_ID_MAX 40

struct imu_raw_mqtt_config {
	struct in_addr address;
	uint16_t port;
	/* Letters, digits, '-' and '_'; used in topics and the client ID. */
	char device_id[IMU_RAW_MQTT_DEVICE_ID_MAX + 1];
	uint8_t session_id[16];
};

struct imu_raw_mqtt_stats {
	bool running, connected;
	size_t queued, queue_high;
	uint32_t published; /* accepted by the socket, not confirmed delivered */
	uint32_t failures, connects, status_published, info_published;
	uint64_t dropped_batches, dropped_accel, dropped_gyro;
	uint64_t lock_wait_count, lock_wait_total_us, lock_wait_max_us;
	uint64_t publish_total_us, publish_max_us, publish_bytes;
};

/* -EBUSY while a previous session is still shutting down, -EINVAL for a bad
 * device ID or port. Counters restart. */
int imu_raw_mqtt_start(const struct imu_raw_mqtt_config *config);
/* Gives a final status up to half a second to leave, then disconnects. */
void imu_raw_mqtt_stop(void);
/* Sink for imu_raw_batch. May wait for the queue mutex; never waits on the
 * network. Returns -EAGAIN for a batch that was dropped. */
int imu_raw_mqtt_submit(void *context, const uint8_t *payload, size_t length);
/* Neither waits on the network. Info is published on every (re)connection and
 * when it changes; status periodically, on (re)connection and when the state
 * changes. Only the acquisition fields of *status are used. Nothing is kept
 * for a disconnected period. */
void imu_raw_mqtt_set_info(const struct imu_raw_info *info);
void imu_raw_mqtt_report(const struct imu_raw_status *status);
void imu_raw_mqtt_get_stats(struct imu_raw_mqtt_stats *stats);
#endif
```
